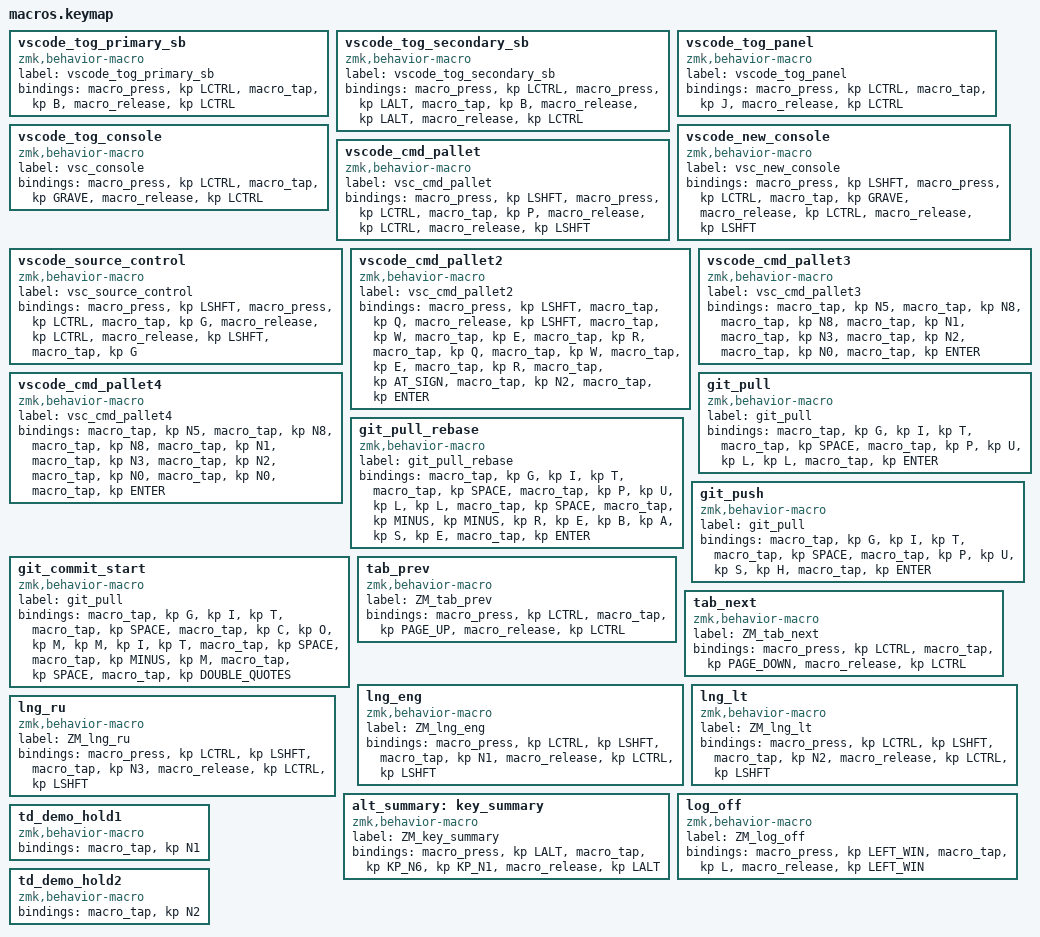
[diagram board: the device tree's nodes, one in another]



// ======================================
// ***===--- Visual Studio Code ---===***
// ======================================

// Toggle Primary Sidebar = Control + B
vscode_tog_primary_sb: vscode_tog_primary_sb {
  label = "vscode_tog_primary_sb";
  compatible = "zmk,behavior-macro";
  #binding-cells = <0>;
  bindings
    = <&macro_press &kp LCTRL>
    , <&macro_tap &kp B>
    , <&macro_release &kp LCTRL>;
};

// Toggle Secondary Sidebar = Control + Alt + B
vscode_tog_secondary_sb: vscode_tog_secondary_sb {
  label = "vscode_tog_secondary_sb";
  compatible = "zmk,behavior-macro";
  #binding-cells = <0>;
  bindings
    = <&macro_press &kp LCTRL>
    , <&macro_press &kp LALT>
    , <&macro_tap &kp B>
    , <&macro_release &kp LALT>
    , <&macro_release &kp LCTRL>;
};

// Toggle Bottom Panel = Control + J
vscode_tog_panel: vscode_tog_panel {
  label = "vscode_tog_panel";
  compatible = "zmk,behavior-macro";
  #binding-cells = <0>;
  bindings
    = <&macro_press &kp LCTRL>
    , <&macro_tap &kp J>
    , <&macro_release &kp LCTRL>;
};

// ======================================

// Control + ` = Toggle VS Code Console
vscode_tog_console: vscode_tog_console {
  label = "vsc_console";
  compatible = "zmk,behavior-macro";
  #binding-cells = <0>;
  bindings
    = <&macro_press &kp LCTRL>
    , <&macro_tap &kp GRAVE>
    , <&macro_release &kp LCTRL>;
};

// Shift + Control + ` = New VS Code Console
vscode_new_console: vscode_new_console {
  label = "vsc_new_console";
  compatible = "zmk,behavior-macro";
  #binding-cells = <0>;
  bindings
    = <&macro_press &kp LSHFT>
    , <&macro_press &kp LCTRL>
    , <&macro_tap &kp GRAVE>
    , <&macro_release &kp LCTRL>
    , <&macro_release &kp LSHFT>;
};

// Shift + Control + P = Command Pallet
vscode_cmd_pallet: vscode_cmd_pallet {
  label = "vsc_cmd_pallet";
  compatible = "zmk,behavior-macro";
  #binding-cells = <0>;
  bindings
    = <&macro_press &kp LSHFT>
    , <&macro_press &kp LCTRL>
    , <&macro_tap &kp P>
    , <&macro_release &kp LCTRL>
    , <&macro_release &kp LSHFT>;
};

// Shift + Control + P = Command Pallet
vscode_source_control: vscode_source_control {
  label = "vsc_source_control";
  compatible = "zmk,behavior-macro";
  #binding-cells = <0>;
  bindings
    = <&macro_press &kp LSHFT>
    , <&macro_press &kp LCTRL>
    , <&macro_tap &kp G>
    , <&macro_release &kp LCTRL>
    , <&macro_release &kp LSHFT>
    , <&macro_tap &kp G>;
};


// =======================================
vscode_cmd_pallet2: vscode_cmd_pallet2 {
  label = "vsc_cmd_pallet2";
  compatible = "zmk,behavior-macro";
  #binding-cells = <0>;
  bindings
    = <&macro_press &kp LSHFT>
    , <&macro_tap &kp Q>
    , <&macro_release &kp LSHFT>
    , <&macro_tap &kp W>
    , <&macro_tap &kp E>
    , <&macro_tap &kp R>
    , <&macro_tap &kp Q>
    , <&macro_tap &kp W>
    , <&macro_tap &kp E>
    , <&macro_tap &kp R>
    , <&macro_tap &kp AT_SIGN>
    , <&macro_tap &kp N2>
    , <&macro_tap &kp ENTER>;
};

vscode_cmd_pallet3: vscode_cmd_pallet3 {
  label = "vsc_cmd_pallet3";
  compatible = "zmk,behavior-macro";
  #binding-cells = <0>;
  bindings
    = <&macro_tap &kp N5>
    , <&macro_tap &kp N8>
    , <&macro_tap &kp N8>
    , <&macro_tap &kp N1>
    , <&macro_tap &kp N3>
    , <&macro_tap &kp N2>
    , <&macro_tap &kp N0>
    , <&macro_tap &kp ENTER>;
};

vscode_cmd_pallet4: vscode_cmd_pallet4 {
  label = "vsc_cmd_pallet4";
  compatible = "zmk,behavior-macro";
  #binding-cells = <0>;
  bindings
    = <&macro_tap &kp N5>
    , <&macro_tap &kp N8>
    , <&macro_tap &kp N8>
    , <&macro_tap &kp N1>
    , <&macro_tap &kp N3>
    , <&macro_tap &kp N2>
    , <&macro_tap &kp N0>
    , <&macro_tap &kp N0>
    , <&macro_tap &kp ENTER>;
};


// ======================================
// ***===---    Git Commands    ---===***
// ======================================

git_pull: git_pull {
  label = "git_pull";
  compatible = "zmk,behavior-macro";
  #binding-cells = <0>;
  bindings
    = <&macro_tap &kp G &kp I &kp T>
    , <&macro_tap &kp SPACE>
    , <&macro_tap &kp P &kp U &kp L &kp L>
    , <&macro_tap &kp ENTER>;
};
git_pull_rebase: git_pull_rebase {
  label = "git_pull_rebase";
  compatible = "zmk,behavior-macro";
  #binding-cells = <0>;
  bindings
    = <&macro_tap &kp G &kp I &kp T>
    , <&macro_tap &kp SPACE>
    , <&macro_tap &kp P &kp U &kp L &kp L>
    , <&macro_tap &kp SPACE>
    , <&macro_tap &kp MINUS &kp MINUS &kp R &kp E &kp B &kp A &kp S &kp E>
    , <&macro_tap &kp ENTER>;
};
git_push: git_push {
  label = "git_pull";
  compatible = "zmk,behavior-macro";
  #binding-cells = <0>;
  bindings
    = <&macro_tap &kp G &kp I &kp T>
    , <&macro_tap &kp SPACE>
    , <&macro_tap &kp P &kp U &kp S &kp H>
    , <&macro_tap &kp ENTER>;
};

git_commit_start: git_commit_start {
  label = "git_pull";
  compatible = "zmk,behavior-macro";
  #binding-cells = <0>;
  bindings
    = <&macro_tap &kp G &kp I &kp T>
    , <&macro_tap &kp SPACE>
    , <&macro_tap &kp C &kp O &kp M &kp M &kp I &kp T>
    , <&macro_tap &kp SPACE>
    , <&macro_tap &kp MINUS &kp M>
    , <&macro_tap &kp SPACE>
    , <&macro_tap &kp DOUBLE_QUOTES>;
};



// ======================================
// ***===---        Misc        ---===***
// ======================================

tab_prev: tab_prev {
        label = "ZM_tab_prev";
        compatible = "zmk,behavior-macro";
        #binding-cells = <0>;
        bindings
                = <&macro_press &kp LCTRL>
                , <&macro_tap &kp PAGE_UP>
                , <&macro_release &kp LCTRL>;
};

tab_next: tab_next {
        label = "ZM_tab_next";
        compatible = "zmk,behavior-macro";
        #binding-cells = <0>;
        bindings
                = <&macro_press &kp LCTRL>
                , <&macro_tap &kp PAGE_DOWN>
                , <&macro_release &kp LCTRL>;
};

// tab_reopen: tab_reopen {
//         label = "ZM_tab_reopen";
//         compatible = "zmk,behavior-macro";
//         #binding-cells = <0>;
//         bindings
//                 = <&macro_press &kp LCTRL(LSHIFT)>
//                 , <&macro_tap &kp T>
//                 , <&macro_release &kp LCTRL(LSHIFT)>;
// };

lng_eng: lng_eng {
        label = "ZM_lng_eng";
        compatible = "zmk,behavior-macro";
        #binding-cells = <0>;
        bindings
                = <&macro_press &kp LCTRL &kp LSHFT>
                , <&macro_tap &kp N1>
                , <&macro_release &kp LCTRL &kp LSHFT>;
};

lng_lt: lng_lt {
        label = "ZM_lng_lt";
        compatible = "zmk,behavior-macro";
        #binding-cells = <0>;
        bindings
                = <&macro_press &kp LCTRL &kp LSHFT>
                , <&macro_tap &kp N2>
                , <&macro_release &kp LCTRL &kp LSHFT>;
};

lng_ru: lng_ru {
        label = "ZM_lng_ru";
        compatible = "zmk,behavior-macro";
        #binding-cells = <0>;
        bindings
                = <&macro_press &kp LCTRL &kp LSHFT>
                , <&macro_tap &kp N3>
                , <&macro_release &kp LCTRL &kp LSHFT>;
};

alt_summary: key_summary {
        label = "ZM_key_summary";
        compatible = "zmk,behavior-macro";
        #binding-cells = <0>;
        bindings
                = <&macro_press &kp LALT>
                , <&macro_tap &kp KP_N6 &kp KP_N1>
                , <&macro_release &kp LALT>;
};

log_off: log_off {
        label = "ZM_log_off";
        compatible = "zmk,behavior-macro";
        #binding-cells = <0>;
        bindings
                = <&macro_press &kp LEFT_WIN>
                , <&macro_tap &kp L>
                , <&macro_release &kp LEFT_WIN>;
};

// =======================================

td_demo_hold1: td_demo_hold1 {
        // label = "ZM_tab_prev";
        compatible = "zmk,behavior-macro";
        #binding-cells = <0>;
        bindings
                = <&macro_tap &kp N1>;
};


td_demo_hold2: td_demo_hold2 {
        // label = "ZM_tab_prev";
        compatible = "zmk,behavior-macro";
        #binding-cells = <0>;
        bindings
                = <&macro_tap &kp N2>;
};
